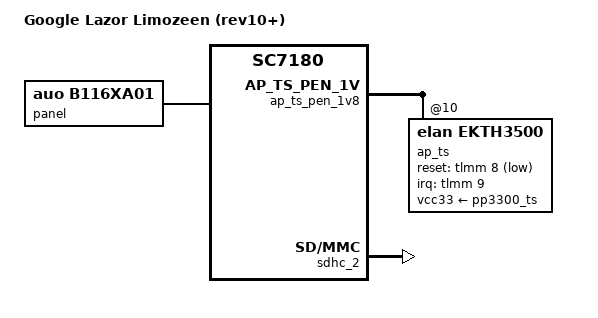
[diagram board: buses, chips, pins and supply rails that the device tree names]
// SPDX-License-Identifier: (GPL-2.0+ OR MIT)
/*
 * Google Lazor Limozeen board device tree source
 *
 * Copyright 2023 Google LLC.
 */

/dts-v1/;

#include "sc7180-trogdor.dtsi"
#include "sc7180-trogdor-parade-ps8640.dtsi"
#include "sc7180-trogdor-lazor.dtsi"
#include "sc7180-trogdor-lte-sku.dtsi"
#include "sc7180-trogdor-rt5682s-sku.dtsi"

/ {
	model = "Google Lazor Limozeen (rev10+)";
	compatible = "google,lazor-sku4", "google,lazor-sku15", "qcom,sc7180";
};

/delete-node/ &ap_ts;

&ap_ts_pen_1v8 {
	ap_ts: touchscreen@10 {
		compatible = "elan,ekth3500";
		reg = <0x10>;
		pinctrl-0 = <&ts_int_l>, <&ts_reset_l>;
		pinctrl-names = "default";

		interrupts = <9 IRQ_TYPE_LEVEL_LOW>;
		interrupt-parent = <&tlmm>;

		vcc33-supply = <&pp3300_ts>;

		reset-gpios = <&tlmm 8 GPIO_ACTIVE_LOW>;
	};
};

&panel {
	compatible = "auo,b116xa01";
};

&sdhc_2 {
	status = "okay";
};
